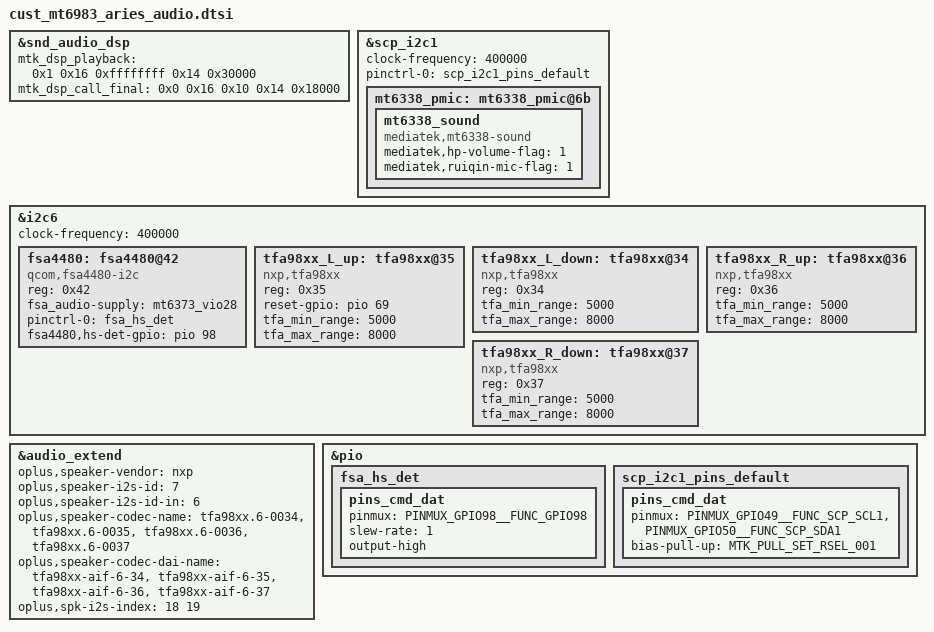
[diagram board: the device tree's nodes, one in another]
// SPDX-License-Identifier: GPL-2.0
/* Copyright (c) 2020 MediaTek Inc. */

&snd_audio_dsp {
	mtk_dsp_playback = <0x1 0x16 0xffffffff 0x14 0x30000>;
	mtk_dsp_call_final = <0x0 0x16 0x10 0x14 0x18000>;
};

&scp_i2c1{
	clock-frequency = <400000>;
	pinctrl-names = "default";
	pinctrl-0 = <&scp_i2c1_pins_default>;
	mt6338_pmic: mt6338_pmic@6b {
		mt6338_sound: mt6338_sound {
			compatible = "mediatek,mt6338-sound";
			mediatek,hp-volume-flag = <1>;
			mediatek,ruiqin-mic-flag = <1>;
		};
	};
};

&i2c6 {
	clock-frequency = <400000>;

	fsa4480: fsa4480@42 {
		compatible = "qcom,fsa4480-i2c";
		reg = <0x42>;
		fsa_audio-supply = <&mt6373_vio28>;
		pinctrl-names = "default";
		pinctrl-0 = <&fsa_hs_det>;
		fsa4480,hs-det-gpio = <&pio 98 0>;
	};

	tfa98xx_L_up: tfa98xx@35 {
		compatible = "nxp,tfa98xx";
		reg = <0x35>;
		reset-gpio = <&pio 69 0>;
		tfa_min_range = <5000>;
		tfa_max_range = <8000>;
		status = "okay";
	};

	tfa98xx_L_down: tfa98xx@34 {
		compatible = "nxp,tfa98xx";
		reg = <0x34>;
		tfa_min_range = <5000>;
		tfa_max_range = <8000>;
		status = "okay";
	};

	tfa98xx_R_up: tfa98xx@36 {
		compatible = "nxp,tfa98xx";
		reg = <0x36>;
		tfa_min_range = <5000>;
		tfa_max_range = <8000>;
		status = "okay";
	};

	tfa98xx_R_down: tfa98xx@37 {
		compatible = "nxp,tfa98xx";
		reg = <0x37>;
		tfa_min_range = <5000>;
		tfa_max_range = <8000>;
		status = "okay";
	};
};

&audio_extend {
 	//for nxp speaker
 	oplus,speaker-vendor = "nxp";
 	oplus,speaker-i2s-id = <7>;
 	oplus,speaker-i2s-id-in = <6>;
 	oplus,speaker-codec-name = "tfa98xx.6-0034","tfa98xx.6-0035","tfa98xx.6-0036","tfa98xx.6-0037";
 	oplus,speaker-codec-dai-name = "tfa98xx-aif-6-34","tfa98xx-aif-6-35","tfa98xx-aif-6-36","tfa98xx-aif-6-37";
	oplus,spk-i2s-index = <18 19>;
};

&pio {
	fsa_hs_det: fsa_hs_det {
		pins_cmd_dat {
			pinmux = <PINMUX_GPIO98__FUNC_GPIO98>;
			slew-rate = <1>;  /*direction 0:in, 1:out*/
			output-high;
		};
	};

	scp_i2c1_pins_default: scp_i2c1_pins_default {
		pins_cmd_dat {
			pinmux = <PINMUX_GPIO49__FUNC_SCP_SCL1>,
					<PINMUX_GPIO50__FUNC_SCP_SDA1>;
			/* 0x0:75k 0x1:3k 0x2:5k 0x3:1.5k */
			/* 0x4:10k 0x5:2k 0x6:4k 0x7:1k */
			bias-pull-up = <MTK_PULL_SET_RSEL_001>;
		};
	};
};
